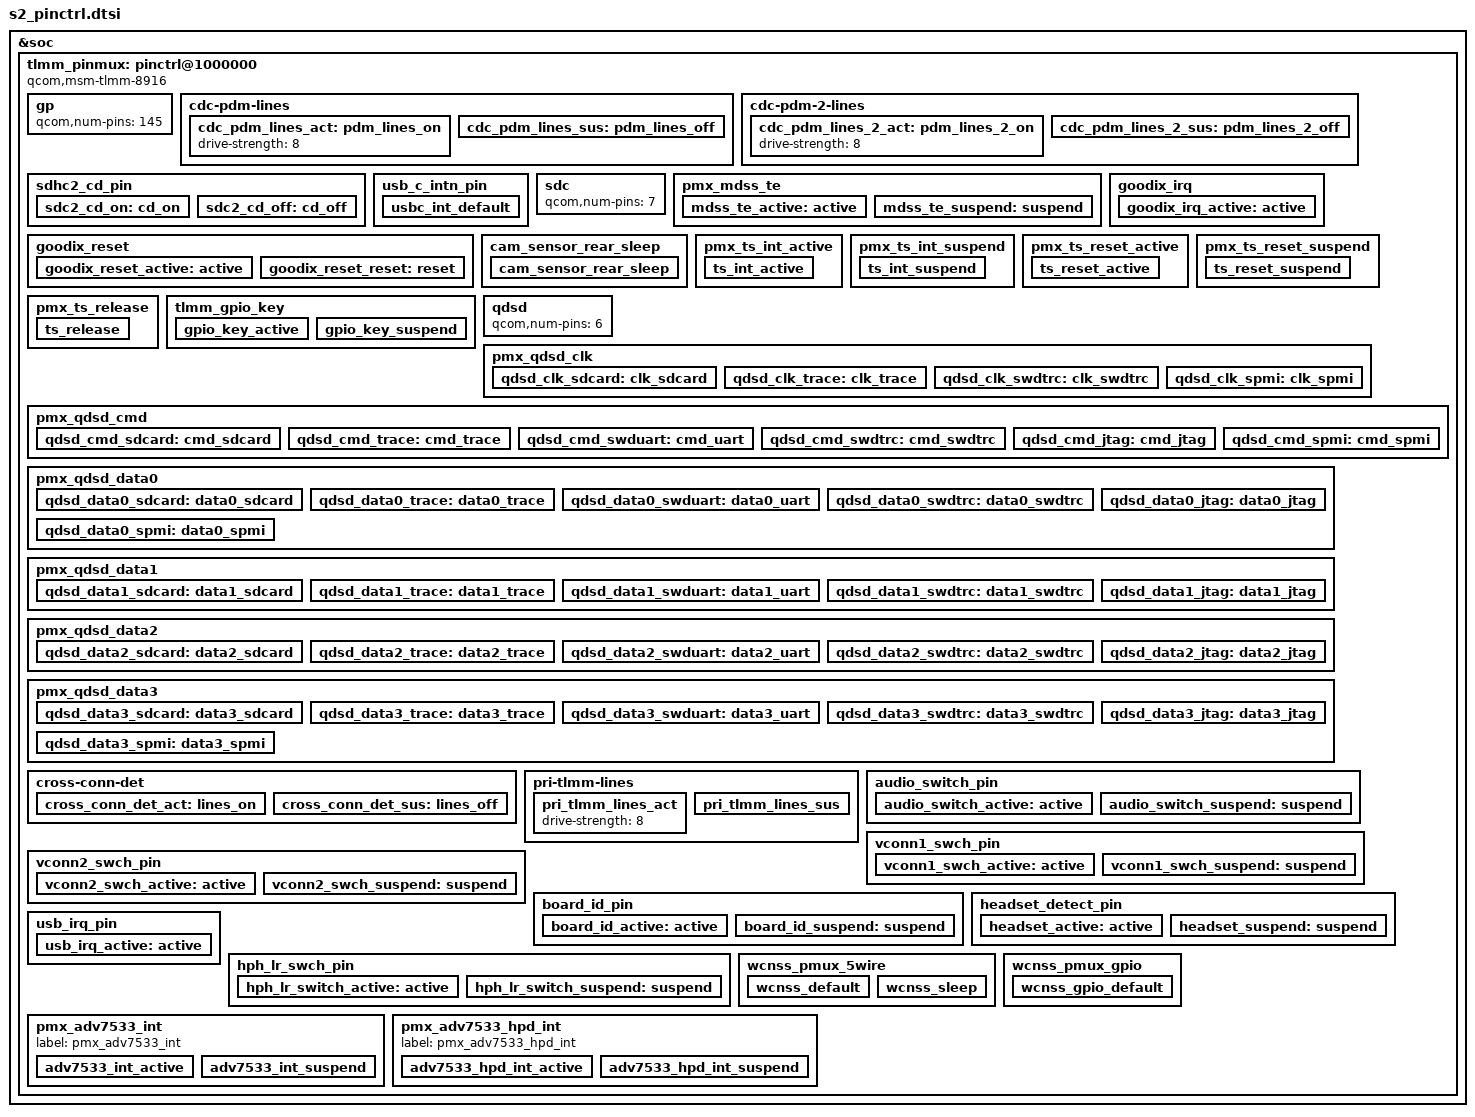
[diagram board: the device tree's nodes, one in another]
/*  Date            Author    	          Why              jira
*/

&soc {
	tlmm_pinmux: pinctrl@1000000 {
		compatible = "qcom,msm-tlmm-8916";
		reg = <0x1000000 0x300000>;
		interrupts = <0 208 0>;

		/*General purpose pins*/
		gp: gp {
			qcom,num-pins = <145>;
			#qcom,pin-cells = <1>;
		};

		cdc-pdm-lines {
			qcom,pins = <&gp 120>, <&gp 121>;
			qcom,num-grp-pins = <2>;
			qcom,pin-func = <1>;
			label = "cdc-pdm-lines";
			cdc_pdm_lines_act: pdm_lines_on {
				drive-strength = <8>;
			};

			cdc_pdm_lines_sus: pdm_lines_off {
				drive-strength = <2>;
				bias-disable;
			};
		};

		cdc-pdm-2-lines {
			qcom,pins = <&gp 116>, <&gp 117>, <&gp 118>, <&gp 119>;
			qcom,num-grp-pins = <4>;
			qcom,pin-func = <2>;
			label = "cdc-pdm-2-lines";
			cdc_pdm_lines_2_act: pdm_lines_2_on {
				drive-strength = <8>;
			};

			cdc_pdm_lines_2_sus: pdm_lines_2_off {
				drive-strength = <2>;
				bias-disable;
			};
		};

		sdhc2_cd_pin {
			qcom,pins = <&gp 100>;
			qcom,num-grp-pins = <1>;
			qcom,pin-func = <0>;
			label = "cd-gpio";
			sdc2_cd_on: cd_on {
				drive-strength = <2>;
				bias-pull-up;
			};
			sdc2_cd_off: cd_off {
				drive-strength = <2>;
				bias-disable;
			};
		};

		usb_c_intn_pin {
			qcom,pins = <&gp 101>, <&gp 102>;
			qcom,num-grp-pins = <2>;
			qcom,pin-func = <0>;
			label = "usb_typec-gpio";
			usbc_int_default: usbc_int_default {
				drive-strength = <2>;	/* 2 MA */
				bias-pull-up;		/* PULL UP*/
			};
		};

		/* SDC pin type */
		sdc: sdc {
			/*
			 * 0-3 for sdc1
			 * 4-6 for sdc2
			 */
			qcom,num-pins = <7>;
			/*
			 * Order of pins:
			 * SDC1: CLK -> 0, CMD -> 1, DATA -> 2, RCLK -> 3
			 * SDC2: CLK -> 4, CMD -> 5, DATA -> 6
			 */
			#qcom,pin-cells = <1>;
		};

		pmx_mdss_te: pmx_mdss_te {
			label = "mdss-te-pin";
			qcom,pin-func = <1>;
			mdss_te_active: active {
				drive-strength = <2>; /* 2 mA */
				bias-pull-down; /* pull down */
				input-debounce = <0>;
			};

			mdss_te_suspend: suspend {
				drive-strength = <2>; /* 2 mA */
				bias-pull-down; /* pull down */
				input-debounce = <0>;
			};
		};

		goodix_reset: goodix_reset {
			qcom,pins = <&gp 110>;
			qcom,num-grp-pins = <1>;
			qcom,pin-func = <0>;
			label = "goodix_reset";
			goodix_reset_active: active {
				drive-strength = <2>;
				bias-disable;
				output-high;
			};
			goodix_reset_reset: reset {
				drive-strength = <2>;
				bias-disable;
				output-low;
			};
		};
		goodix_irq: goodix_irq {
			qcom,pins = <&gp 106>;
			qcom,num-grp-pins = <1>;
			qcom,pin-func = <0>;
			label = "goodix_irq";
			goodix_irq_active: active {
				drive-strength = <2>;
				bias-disable;
				input-enable;
			};
		};

		cam_sensor_rear_sleep {
			/*STANDBY  AVDD  DVDD*/
			qcom,pins = <&gp 35>,<&gp 36>,<&gp 143>,<&gp 144>;
			qcom,num-grp-pins = <4>;
			label = "cam_sensor_rear_sleep";
			/*suspended state */
			cam_sensor_rear_sleep: cam_sensor_rear_sleep {
				drive-strength = <2>; /* 2 MA */
				bias-disable; /* No PULL */
			};
		};

		/* add pingrp for touchscreen */
		pmx_ts_int_active {
			qcom,pins = <&gp 65>;
			qcom,pin-func = <0>;
			qcom,num-grp-pins = <1>;
			label = "pmx_ts_int_active";

			ts_int_active: ts_int_active {
				drive-strength = <8>;
				bias-disable;
				input-enable;
			};
		};

		pmx_ts_int_suspend {
			qcom,pins = <&gp 65>;
			qcom,pin-func = <0>;
			qcom,num-grp-pins = <1>;
			label = "pmx_ts_int_suspend";

			ts_int_suspend: ts_int_suspend {
				drive-strength = <2>;
				output-low;
			};
		};

		pmx_ts_reset_active {
			qcom,pins = <&gp 64>;
			qcom,pin-func = <0>;
			qcom,num-grp-pins = <1>;
			label = "pmx_ts_reset_active";

			ts_reset_active: ts_reset_active {
				drive-strength = <8>;
				bias-pull-up;
			};
		};

		pmx_ts_reset_suspend {
			qcom,pins = <&gp 64>;
			qcom,pin-func = <0>;
			qcom,num-grp-pins = <1>;
			label = "pmx_ts_reset_suspend";

			ts_reset_suspend: ts_reset_suspend {
				drive-strength = <2>;
				output-low;
			};
		};

		pmx_ts_release {
			qcom,pins = <&gp 65>, <&gp 64>;
			qcom,num-grp-pins = <2>;
			label = "pmx_ts_release";

			ts_release: ts_release {
				drive-strength = <2>;
				bias-pull-down;
			};
		};

		tlmm_gpio_key: tlmm_gpio_key {
			qcom,pins = <&gp 113>;
			qcom,pin-func = <0>;
			qcom,num-grp-pins = <1>;
			label = "tlmm_gpio_key";

			gpio_key_active: gpio_key_active {
				drive-strength = <2>;
				bias-pull-up;
			};

			gpio_key_suspend: gpio_key_suspend {
				drive-strength = <2>;
				bias-pull-up;
			};
		};

		/* QDSD pin type */
		qdsd: qdsd {
			/* 0-> clk, 1 -> cmd, 2->data0, 3->data1, 4->data2, 5->data3 */
			qcom,num-pins = <6>;

			#qcom,pin-cells = <1>;
		};

		pmx_qdsd_clk {
			qcom,pins = <&qdsd 0>;
			qcom,num-grp-pins = <1>;
			label = "qdsd-clk";
			qdsd_clk_sdcard: clk_sdcard {
				bias-disable; /* NO pull */
				drive-strength = <7>; /* 7 MA */
			};

			qdsd_clk_trace: clk_trace {
				bias-pull-down; /* pull down */
				drive-strength = <0>; /* 0 MA */
			};

			qdsd_clk_swdtrc: clk_swdtrc {
				bias-pull-down; /* pull down */
				drive-strength = <0>; /* 0 MA */
			};

			qdsd_clk_spmi: clk_spmi {
				bias-pull-down; /* pull down */
				drive-strength = <0>; /* 0 MA */
			};
		};

		pmx_qdsd_cmd {
			qcom,pins = <&qdsd 1>;
			qcom,num-grp-pins = <1>;
			label = "qdsd-cmd";
			qdsd_cmd_sdcard: cmd_sdcard {
				bias-pull-down; /* pull down */
				drive-strength = <3>; /* 3 MA */
			};

			qdsd_cmd_trace: cmd_trace {
				bias-pull-down; /* pull down */
				drive-strength = <0>; /* 0 MA */
			};

			qdsd_cmd_swduart: cmd_uart {
				bias-pull-up; /* pull up */
				drive-strength = <0>; /* 0 MA */
			};

			qdsd_cmd_swdtrc: cmd_swdtrc {
				bias-pull-up; /* pull up */
				drive-strength = <0>; /* 0 MA */
			};

			qdsd_cmd_jtag: cmd_jtag {
				bias-disable; /* NO pull */
				drive-strength = <3>; /* 3 MA */
			};

			qdsd_cmd_spmi: cmd_spmi {
				bias-pull-down; /* pull down */
				drive-strength = <4>; /* 4 MA */
			};
		};

		pmx_qdsd_data0 {
			qcom,pins = <&qdsd 2>;
			qcom,num-grp-pins = <1>;
			label = "qdsd-data0";
			qdsd_data0_sdcard: data0_sdcard {
				bias-pull-down; /* pull down */
				drive-strength = <3>; /* 3 MA */
			};

			qdsd_data0_trace: data0_trace {
				bias-pull-down; /* pull down */
				drive-strength = <3>; /* 3 MA */
			};

			qdsd_data0_swduart: data0_uart {
				bias-pull-down; /* pull down */
				drive-strength = <0>; /* 0 MA */
			};

			qdsd_data0_swdtrc: data0_swdtrc {
				bias-pull-down; /* pull down */
				drive-strength = <0>; /* 0 MA */
			};

			qdsd_data0_jtag: data0_jtag {
				bias-pull-up; /* pull up */
				drive-strength = <0>; /* 0 MA */
			};

			qdsd_data0_spmi: data0_spmi {
				bias-pull-down; /* pull down */
				drive-strength = <0>; /* 0 MA */
			};
		};

		pmx_qdsd_data1 {
			qcom,pins = <&qdsd 3>;
			qcom,num-grp-pins = <1>;
			label = "qdsd-data1";
			qdsd_data1_sdcard: data1_sdcard {
				bias-pull-down; /* pull down */
				drive-strength = <3>; /* 3 MA */
			};

			qdsd_data1_trace: data1_trace {
				bias-pull-down; /* pull down */
				drive-strength = <3>; /* 3 MA */
			};

			qdsd_data1_swduart: data1_uart {
				bias-pull-down; /* pull down */
				drive-strength = <0>; /* 0 MA */
			};

			qdsd_data1_swdtrc: data1_swdtrc {
				bias-pull-down; /* pull down */
				drive-strength = <0>; /* 0 MA */
			};

			qdsd_data1_jtag: data1_jtag {
				bias-pull-down; /* pull down */
				drive-strength = <0>; /* 0 MA */
			};
		};

		pmx_qdsd_data2 {
			qcom,pins = <&qdsd 4>;
			qcom,num-grp-pins = <1>;
			label = "qdsd-data2";
			qdsd_data2_sdcard: data2_sdcard {
				bias-pull-down; /* pull down */
				drive-strength = <3>; /* 3 MA */
			};

			qdsd_data2_trace: data2_trace {
				bias-pull-down; /* pull down */
				drive-strength = <3>; /* 3 MA */
			};

			qdsd_data2_swduart: data2_uart {
				bias-pull-down; /* pull down */
				drive-strength = <0>; /* 0 MA */
			};

			qdsd_data2_swdtrc: data2_swdtrc {
				bias-pull-down; /* pull down */
				drive-strength = <0>; /* 0 MA */
			};

			qdsd_data2_jtag: data2_jtag {
				bias-pull-up; /* pull up */
				drive-strength = <3>; /* 3 MA */
			};
		};

		pmx_qdsd_data3 {
			qcom,pins = <&qdsd 5>;
			qcom,num-grp-pins = <1>;
			label = "qdsd-data3";
			qdsd_data3_sdcard: data3_sdcard {
				bias-pull-down; /* pull down */
				drive-strength = <3>; /* 3 MA */
			};

			qdsd_data3_trace: data3_trace {
				bias-pull-down; /* pull down */
				drive-strength = <3>; /* 3 MA */
			};

			qdsd_data3_swduart: data3_uart {
				bias-pull-up; /* pull up */
				drive-strength = <0>; /* 0 MA */
			};

			qdsd_data3_swdtrc: data3_swdtrc {
				bias-pull-up; /* pull up */
				drive-strength = <0>; /* 0 MA */
			};

			qdsd_data3_jtag: data3_jtag {
				bias-pull-up; /* pull up */
				drive-strength = <0>; /* 0 MA */
			};

			qdsd_data3_spmi: data3_spmi {
				bias-pull-down; /* pull down */
				drive-strength = <3>; /* 3 MA */
			};
		};

		cross-conn-det {
			qcom,pins = <&gp 69>;
			qcom,num-grp-pins = <1>;
			qcom,pin-func = <0>;
			label = "cross-conn-det-sw";
			cross_conn_det_act: lines_on {
				drive-strength = <8>;
				/delete-property/ output-low;
				bias-pull-down;
			};

			cross_conn_det_sus: lines_off {
				drive-strength = <2>;
				bias-pull-down;
			};
		};

		pri-tlmm-lines {
			qcom,pins = <&gp 123>, <&gp 124>, <&gp 125>, <&gp 127>;
			qcom,num-grp-pins = <4>;
			qcom,pin-func = <1>;
			label = "pri-tlmm-lines";
			pri_tlmm_lines_act: pri_tlmm_lines_act {
				drive-strength = <8>;
			};
			pri_tlmm_lines_sus:  pri_tlmm_lines_sus {
				drive-strength = <2>;
				bias-pull-down;
			};
		};

		audio_switch_pin {
			qcom,pins = <&gp 111>;
			qcom,pin-func = <0>;
			qcom,num-grp-pins = <1>;
			label = "audio_switch_pin";
			audio_switch_active: active {
				drive-strength = <6>;
				bias-pull-up;
			};
			audio_switch_suspend: suspend {
				drive-strength = <2>;
				bias-pull-down;
			};
		};

		vconn1_swch_pin {
			qcom,pins = <&gp 20>;
			qcom,pin-func = <0>;
			qcom,num-grp-pins = <1>;
			label = "vconn1_swch_pin";
			vconn1_swch_active: active {
				drive-strength = <6>;
				bias-pull-up;
			};
			vconn1_swch_suspend: suspend {
				drive-strength = <2>;
				bias-pull-down;
			};
		};

		vconn2_swch_pin {
			qcom,pins = <&gp 115>;
			qcom,pin-func = <0>;
			qcom,num-grp-pins = <1>;
			label = "vconn2_swch_pin";
			vconn2_swch_active: active {
				drive-strength = <6>;
				bias-pull-up;
			};
			vconn2_swch_suspend: suspend {
				drive-strength = <2>;
				bias-pull-down;
			};
		};

		board_id_pin {
			qcom,pins = <&gp 62>, <&gp 63>, <&gp 66>;
			qcom,pin-func = <0>;
			qcom,num-grp-pins = <3>;
			label = "board_id_pin";
			board_id_active: active {
				drive-strength = <2>;
				input-enable;
				bias-pull-up;
			};
			board_id_suspend: suspend {
				drive-strength = <2>;
				input-enable;
				bias-pull-down;
			};
		};

		headset_detect_pin {
			qcom,pins = <&gp 114>;
			qcom,pin-func = <0>;
			qcom,num-grp-pins = <1>;
			label = "headset_detect_pin";
			headset_active: active {
				drive-strength = <2>;
				bias-disable; /* NO pull */
			};
			headset_suspend: suspend {
				drive-strength = <2>;
				bias-disable; /* NO pull */
			};
		};

		usb_irq_pin {
			qcom,pins = <&gp 21>;
			qcom,pin-func = <0>;
			qcom,num-grp-pins = <1>;
			label = "ti_usb_enb_irq";
			usb_irq_active: active {
				drive-strength = <2>;
				bias-disable; /* NO pull */
			};
		};

		hph_lr_swch_pin {
			qcom,pins = <&gp 16>;
			qcom,pin-func = <0>;
			qcom,num-grp-pins = <1>;
			label = "hph_lr_swch_pin";
			hph_lr_switch_active: active {
				drive-strength = <6>;
				bias-pull-up;
			};
			hph_lr_switch_suspend: suspend {
				drive-strength = <2>;
				bias-pull-down;
			};
		};
		wcnss_pmux_5wire: wcnss_pmux_5wire {
			/* Uses general purpose pins */
			qcom,pins = <&gp 40>, <&gp 41>,
				    <&gp 42>, <&gp 43>,
				    <&gp 44>;
			qcom,num-grp-pins = <5>;
			qcom,pin-func = <1>;
			label = "wcnss_5wire_pins";
			/* Active configuration of bus pins */
			wcnss_default: wcnss_default {
				drive-strength = <6>; /* 6 MA */
				bias-pull-up; /* PULL UP */
			};
			wcnss_sleep: wcnss_sleep {
				drive-strength = <2>; /* 2 MA */
				bias-pull-down; /* PULL Down */
			};
		};

		wcnss_pmux_gpio: wcnss_pmux_gpio {
			/* Uses general purpose pins */
			qcom,pins = <&gp 40>, <&gp 41>,
				    <&gp 42>, <&gp 43>,
				    <&gp 44>;
			qcom,num-grp-pins = <5>;
			qcom,pin-func = <0>;
			label = "wcnss_5gpio_pins";
			/* Active configuration of bus pins */
			wcnss_gpio_default: wcnss_gpio_default {
				drive-strength = <6>; /* 6 MA */
				bias-pull-up; /* PULL UP */
			};
		};

		pmx_adv7533_int: pmx_adv7533_int {
			label = "pmx_adv7533_int";
			adv7533_int_active: adv7533_int_active {
				drive-strength = <16>;
				bias-disable;
			};

			adv7533_int_suspend: adv7533_int_suspend {
				drive-strength = <16>;
				bias-disable;
			};
		};

		pmx_adv7533_hpd_int: pmx_adv7533_hpd_int {
			label = "pmx_adv7533_hpd_int";
			adv7533_hpd_int_active: adv7533_hpd_int_active {
				drive-strength = <16>;
				bias-disable;
			};

			adv7533_hpd_int_suspend: adv7533_hpd_int_suspend {
				drive-strength = <16>;
				bias-disable;
			};
		};

/*
		pmx_rd_nfc_int {
			qcom,pins = <&gp 21>;
			qcom,pin-func = <0>;
			qcom,num-grp-pins = <1>;
			label = "pmx_nfc_int";

			nfc_int_active: active {
				drive-strength = <6>;
				bias-pull-up;
			};

			nfc_int_suspend: suspend {
				drive-strength = <6>;
				bias-pull-up;
			};
		};

		pmx_nfc_reset {
			qcom,pins = <&gp 20>;
			qcom,pin-func = <0>;
			qcom,num-grp-pins = <1>;
			label = "pmx_nfc_disable";

			nfc_disable_active: active {
				drive-strength = <6>;
				bias-pull-up;
			};

			nfc_disable_suspend: suspend {
				drive-strength = <6>;
				bias-disable;
			};
		};
*/
	};
};
